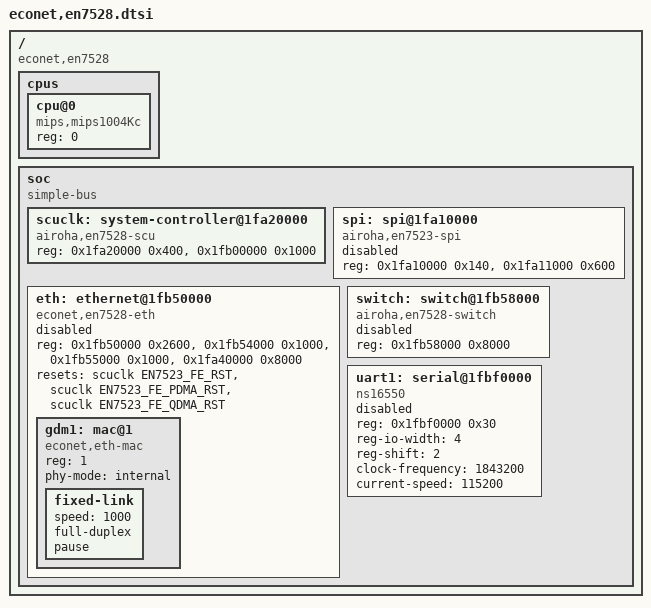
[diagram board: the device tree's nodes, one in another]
// SPDX-License-Identifier: (GPL-2.0-only OR BSD-2-Clause)

#include <dt-bindings/reset/airoha,en7523-reset.h>

/ {
	compatible = "econet,en7528";
	#address-cells = <1>;
	#size-cells = <1>;

	cpus {
		#address-cells = <1>;
		#size-cells = <0>;

		cpu@0 {
			compatible = "mips,mips1004Kc";
			device_type = "cpu";
			reg = <0>;
		};
	};

	soc {
		compatible = "simple-bus";
		#address-cells = <1>;
		#size-cells = <1>;
		ranges;

		scuclk: system-controller@1fa20000 {
			compatible = "airoha,en7528-scu";
			reg = <0x1fa20000 0x400>,
			      <0x1fb00000 0x1000>;
			#clock-cells = <1>;
			#reset-cells = <1>;
		};

		spi: spi@1fa10000 {
			compatible = "airoha,en7523-spi";
			reg = <0x1fa10000 0x140>,
			      <0x1fa11000 0x600>;
			#address-cells = <1>;
			#size-cells = <0>;
			status = "disabled";
		};

		eth: ethernet@1fb50000 {
			compatible = "econet,en7528-eth";
			reg = <0x1fb50000 0x2600>,
			      <0x1fb54000 0x1000>,
			      <0x1fb55000 0x1000>,
			      <0x1fa40000 0x8000>;
			reg-names = "fe", "qdma0", "qdma1", "gdmp";
			resets = <&scuclk EN7523_FE_RST>,
				 <&scuclk EN7523_FE_PDMA_RST>,
				 <&scuclk EN7523_FE_QDMA_RST>;
			reset-names = "fe", "pdma", "qdma";
			#address-cells = <1>;
			#size-cells = <0>;
			status = "disabled";

			gdm1: mac@1 {
				compatible = "econet,eth-mac";
				reg = <1>;
				phy-mode = "internal";
	
				fixed-link {
					speed = <1000>;
					full-duplex;
					pause;
				};
			};
		};

		switch: switch@1fb58000 {
			compatible = "airoha,en7528-switch", "airoha,en7523-switch";
			reg = <0x1fb58000 0x8000>;
			status = "disabled";
		};

		uart1: serial@1fbf0000 {
			compatible = "ns16550";
			reg = <0x1fbf0000 0x30>;
			reg-io-width = <4>;
			reg-shift = <2>;
			clock-frequency = <1843200>;
			current-speed = <115200>;
			status = "disabled";
		};
	};
};
